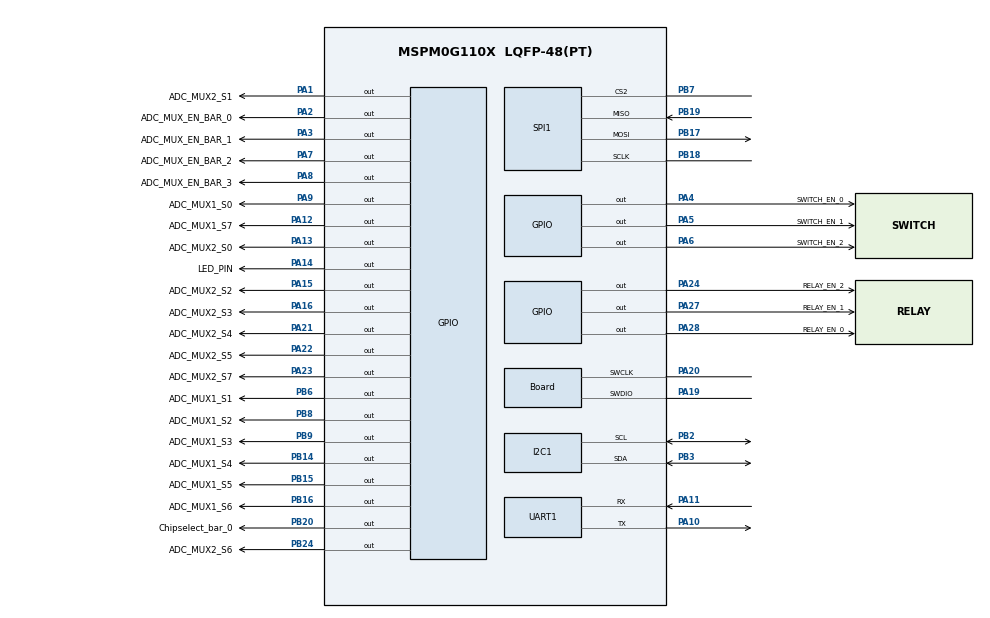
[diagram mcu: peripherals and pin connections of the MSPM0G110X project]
/**
 * @cliArgs --device "MSPM0G110X" --package "LQFP-48(PT)" --part "Default" --product "mspm0_sdk@2.00.00.03"
 * @versions {"tool":"1.19.0+3426"}
 */

/**
 * Import the modules used in this configuration.
 */
const GPIO          = scripting.addModule("/ti/driverlib/GPIO", {}, false);
const GPIO1         = GPIO.addInstance();
const GPIO2         = GPIO.addInstance();
const GPIO3         = GPIO.addInstance();
const GPIO4         = GPIO.addInstance();
const GPIO5         = GPIO.addInstance();
const GPIO6         = GPIO.addInstance();
const GPIO7         = GPIO.addInstance();
const GPIO8         = GPIO.addInstance();
const I2C           = scripting.addModule("/ti/driverlib/I2C", {}, false);
const I2C1          = I2C.addInstance();
const SPI           = scripting.addModule("/ti/driverlib/SPI", {}, false);
const SPI1          = SPI.addInstance();
const SYSCTL        = scripting.addModule("/ti/driverlib/SYSCTL");
const TIMER         = scripting.addModule("/ti/driverlib/TIMER", {}, false);
const TIMER1        = TIMER.addInstance();
const TIMER2        = TIMER.addInstance();
const UART          = scripting.addModule("/ti/driverlib/UART", {}, false);
const UART1         = UART.addInstance();
const WWDT          = scripting.addModule("/ti/driverlib/WWDT", {}, false);
const WWDT1         = WWDT.addInstance();
const ProjectConfig = scripting.addModule("/ti/project_config/ProjectConfig");

/**
 * Write custom configuration values to the imported modules.
 */
GPIO1.$name                         = "LED";
GPIO1.associatedPins[0].$name       = "LED_PIN";
GPIO1.associatedPins[0].pin.$assign = "PA14";

const Board                       = scripting.addModule("/ti/driverlib/Board", {}, false);
Board.peripheral.$assign          = "DEBUGSS";
Board.peripheral.swclkPin.$assign = "PA20";
Board.peripheral.swdioPin.$assign = "PA19";

GPIO2.$name                          = "MUX1";
GPIO2.associatedPins.create(5);
GPIO2.associatedPins[0].$name        = "ADC_MUX_EN_BAR_0";
GPIO2.associatedPins[0].initialValue = "SET";
GPIO2.associatedPins[0].pin.$assign  = "PA2";
GPIO2.associatedPins[1].$name        = "ADC_MUX1_S0";
GPIO2.associatedPins[1].pin.$assign  = "PA9";
GPIO2.associatedPins[2].$name        = "ADC_MUX1_S1";
GPIO2.associatedPins[2].pin.$assign  = "PB6";
GPIO2.associatedPins[3].$name        = "ADC_MUX1_S2";
GPIO2.associatedPins[3].pin.$assign  = "PB8";
GPIO2.associatedPins[4].$name        = "ADC_MUX1_S3";
GPIO2.associatedPins[4].pin.$assign  = "PB9";

GPIO3.$name                          = "MUX2";
GPIO3.associatedPins.create(5);
GPIO3.associatedPins[0].$name        = "ADC_MUX_EN_BAR_1";
GPIO3.associatedPins[0].initialValue = "SET";
GPIO3.associatedPins[0].pin.$assign  = "PA3";
GPIO3.associatedPins[1].$name        = "ADC_MUX1_S4";
GPIO3.associatedPins[1].pin.$assign  = "PB14";
GPIO3.associatedPins[2].$name        = "ADC_MUX1_S5";
GPIO3.associatedPins[2].pin.$assign  = "PB15";
GPIO3.associatedPins[3].$name        = "ADC_MUX1_S6";
GPIO3.associatedPins[3].pin.$assign  = "PB16";
GPIO3.associatedPins[4].$name        = "ADC_MUX1_S7";
GPIO3.associatedPins[4].pin.$assign  = "PA12";

GPIO4.$name                          = "MUX3";
GPIO4.associatedPins.create(5);
GPIO4.associatedPins[0].$name        = "ADC_MUX_EN_BAR_2";
GPIO4.associatedPins[0].initialValue = "SET";
GPIO4.associatedPins[0].pin.$assign  = "PA7";
GPIO4.associatedPins[1].$name        = "ADC_MUX2_S0";
GPIO4.associatedPins[1].pin.$assign  = "PA13";
GPIO4.associatedPins[2].$name        = "ADC_MUX2_S1";
GPIO4.associatedPins[2].pin.$assign  = "PA1";
GPIO4.associatedPins[3].$name        = "ADC_MUX2_S2";
GPIO4.associatedPins[3].pin.$assign  = "PA15";
GPIO4.associatedPins[4].$name        = "ADC_MUX2_S3";
GPIO4.associatedPins[4].pin.$assign  = "PA16";

GPIO5.$name                          = "MUX4";
GPIO5.associatedPins.create(5);
GPIO5.associatedPins[0].$name        = "ADC_MUX_EN_BAR_3";
GPIO5.associatedPins[0].initialValue = "SET";
GPIO5.associatedPins[0].pin.$assign  = "PA8";
GPIO5.associatedPins[1].$name        = "ADC_MUX2_S4";
GPIO5.associatedPins[1].pin.$assign  = "PA21";
GPIO5.associatedPins[2].$name        = "ADC_MUX2_S5";
GPIO5.associatedPins[2].pin.$assign  = "PA22";
GPIO5.associatedPins[3].$name        = "ADC_MUX2_S6";
GPIO5.associatedPins[3].pin.$assign  = "PB24";
GPIO5.associatedPins[4].$name        = "ADC_MUX2_S7";
GPIO5.associatedPins[4].pin.$assign  = "PA23";

GPIO6.$name                          = "Chipselect_bar";
GPIO6.associatedPins[0].$name        = "Chipselect_bar_0";
GPIO6.associatedPins[0].initialValue = "SET";
GPIO6.associatedPins[0].pin.$assign  = "PB20";

GPIO7.$name                         = "Switch_EN";
GPIO7.associatedPins.create(3);
GPIO7.associatedPins[0].$name       = "SWITCH_EN_0";
GPIO7.associatedPins[0].pin.$assign = "PA4";
GPIO7.associatedPins[1].$name       = "SWITCH_EN_1";
GPIO7.associatedPins[1].pin.$assign = "PA5";
GPIO7.associatedPins[2].$name       = "SWITCH_EN_2";
GPIO7.associatedPins[2].pin.$assign = "PA6";

GPIO8.$name                          = "Relay_EN";
GPIO8.associatedPins.create(3);
GPIO8.associatedPins[0].$name        = "RELAY_EN_1";
GPIO8.associatedPins[0].pin.$assign  = "PA27";
GPIO8.associatedPins[1].$name        = "RELAY_EN_0";
GPIO8.associatedPins[1].initialValue = "SET";
GPIO8.associatedPins[1].pin.$assign  = "PA28";
GPIO8.associatedPins[2].$name        = "RELAY_EN_2";
GPIO8.associatedPins[2].pin.$assign  = "PA24";

I2C1.$name                     = "I2C_0";
I2C1.basicEnableController     = true;
I2C1.advControllerTXFIFOTRIG   = "BYTES_1";
I2C1.intController             = ["ARBITRATION_LOST","EVENT1_DMA_DONE","EVENT2_DMA_DONE","NACK","RXFIFO_FULL","RXFIFO_TRIGGER","RX_DONE","START","STOP","TXFIFO_EMPTY","TXFIFO_TRIGGER","TX_DONE"];
I2C1.peripheral.$assign        = "I2C1";
I2C1.peripheral.sdaPin.$assign = "PB3";
I2C1.peripheral.sclPin.$assign = "PB2";
I2C1.sdaPinConfig.$name        = "ti_driverlib_gpio_GPIOPinGeneric2";
I2C1.sclPinConfig.$name        = "ti_driverlib_gpio_GPIOPinGeneric3";

SPI1.$name                      = "SPI_0";
SPI1.targetBitRate              = 1000000;
SPI1.enableDMAEvent1            = false;
SPI1.enableDMAEvent2            = false;
SPI1.dataSize                   = 16;
SPI1.enabledInterrupts          = ["IDLE","RX","TX"];
SPI1.chipSelect                 = ["2"];
SPI1.overrideRetention          = true;
SPI1.peripheral.$assign         = "SPI0";
SPI1.peripheral.sclkPin.$assign = "PB18";
SPI1.peripheral.mosiPin.$assign = "PB17";
SPI1.peripheral.misoPin.$assign = "PB19";
SPI1.peripheral.cs2Pin.$assign  = "PB7";
SPI1.sclkPinConfig.$name        = "ti_driverlib_gpio_GPIOPinGeneric4";
SPI1.mosiPinConfig.$name        = "ti_driverlib_gpio_GPIOPinGeneric5";
SPI1.misoPinConfig.$name        = "ti_driverlib_gpio_GPIOPinGeneric6";
SPI1.cs2PinConfig.$name         = "ti_driverlib_gpio_GPIOPinGeneric7";

SYSCTL.forceDefaultClkConfig = true;
SYSCTL.peripheral.$assign    = "SYSCTL";

TIMER1.$name              = "TIMER_0";
TIMER1.interrupts         = ["LOAD"];
TIMER1.timerMode          = "ONE_SHOT_UP";
TIMER1.peripheral.$assign = "TIMG0";

TIMER2.$name               = "TIMER_2";
TIMER2.timerClkPrescale    = 32;
TIMER2.interrupts          = ["ZERO"];
TIMER2.timerMode           = "PERIODIC_UP";
TIMER2.timerPeriod         = "65.535 ms";
TIMER2.retentionRestoreCnt = true;
TIMER2.overrideRetention   = true;
TIMER2.peripheral.$assign  = "TIMG7";

UART1.$name                    = "UART_0";
UART1.txFifoThreshold          = "DL_UART_TX_FIFO_LEVEL_ONE_ENTRY";
UART1.enableFIFO               = true;
UART1.rxFifoThreshold          = "DL_UART_RX_FIFO_LEVEL_1_4_FULL";
UART1.enabledInterrupts        = ["EOT_DONE","RX","RXD_NEG_EDGE","RXD_POS_EDGE","RX_TIMEOUT_ERROR","TX"];
UART1.targetBaudRate           = 115200;
UART1.peripheral.$assign       = "UART0";
UART1.peripheral.rxPin.$assign = "PA11";
UART1.peripheral.txPin.$assign = "PA10";
UART1.txPinConfig.$name        = "ti_driverlib_gpio_GPIOPinGeneric0";
UART1.rxPinConfig.$name        = "ti_driverlib_gpio_GPIOPinGeneric1";

WWDT1.$name              = "WWDT0";
WWDT1.periodCount        = "15";
WWDT1.clockDivider       = "2";
WWDT1.interruptPriority  = "0";
WWDT1.peripheral.$assign = "WWDT0";

ProjectConfig.deviceSpin = "MSPM0G1107";
scripting.suppress("Migrating requires going through the Switch Board or Device menu in the Device View section\\.", ProjectConfig, "deviceSpin");
